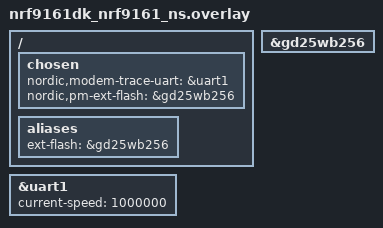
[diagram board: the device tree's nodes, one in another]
/*
 * Copyright (c) 2025 Nordic Semiconductor ASA
 *
 * SPDX-License-Identifier: LicenseRef-Nordic-5-Clause
 */

/ {
	/* Configure partition manager to use gd25wb256 as the external flash */
	chosen {
		nordic,modem-trace-uart = &uart1;
		nordic,pm-ext-flash = &gd25wb256;
	};

	aliases {
		ext-flash = &gd25wb256;
	};
};

&gd25wb256 {
	status = "okay";
};

&uart1 {
	status = "okay";
	current-speed = <1000000>;
};
